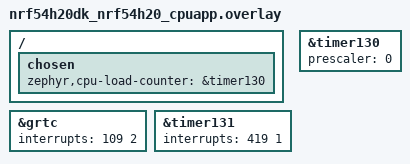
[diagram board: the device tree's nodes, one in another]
/* SPDX-License-Identifier: Apache-2.0 */

&grtc {
	/delete-property/ child-owned-channels;
	interrupts = <109 2>;
};

test_timer: &timer131 {
	interrupts = <419 1>;
	status = "okay";
};

&timer130 {
	prescaler = <0>;
	status = "okay";
};

/ {
	chosen {
		zephyr,cpu-load-counter = &timer130;
	};
};
